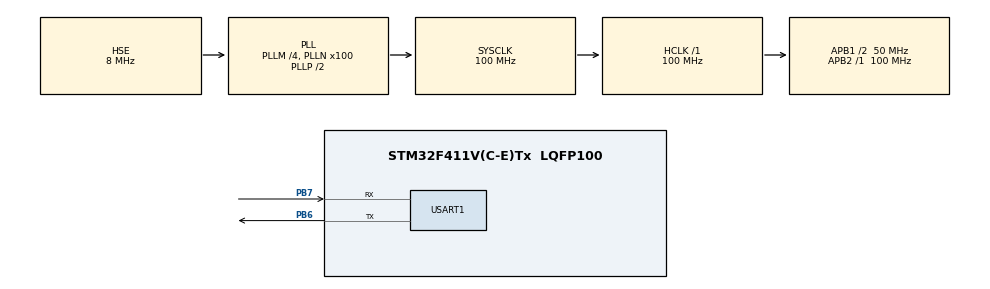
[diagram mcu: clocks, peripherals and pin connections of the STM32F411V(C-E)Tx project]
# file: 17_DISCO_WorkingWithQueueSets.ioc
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FREERTOS.Tasks01=defaultTask,24,128,StartDefaultTask,Default,NULL,Dynamic,NULL,NULL
FREERTOS.configUSE_NEWLIB_REENTRANT=0
FREERTOS.configUSE_PREEMPTION=1
Mcu.Family=STM32F4
Mcu.Name=STM32F411V(C-E)Tx
Mcu.Package=LQFP100
NVIC.PriorityGroup=NVIC_PRIORITYGROUP_4
NVIC.TIM1_UP_TIM10_IRQn=true\:15\:0\:false\:false\:true\:false\:false\:true\:true
NVIC.TimeBase=TIM1_UP_TIM10_IRQn
NVIC.TimeBaseIP=TIM1
PA13.GPIO_Label=SWDIO
PA13.Mode=Serial_Wire
PA13.Signal=SYS_JTMS-SWDIO
PA14.GPIO_Label=SWCLK
PA14.Mode=Serial_Wire
PA14.Signal=SYS_JTCK-SWCLK
PB3.GPIO_Label=SWO
PB3.Signal=SYS_JTDO-SWO
PB6.Mode=Asynchronous
PB6.Signal=USART1_TX
PB7.Mode=Asynchronous
PB7.Signal=USART1_RX
PH0\ -\ OSC_IN.GPIO_Label=PH0-OSC_IN
PH0\ -\ OSC_IN.Mode=HSE-External-Oscillator
PH0\ -\ OSC_IN.Signal=RCC_OSC_IN
PH1\ -\ OSC_OUT.GPIO_Label=PH1-OSC_OUT
PH1\ -\ OSC_OUT.Mode=HSE-External-Oscillator
PH1\ -\ OSC_OUT.Signal=RCC_OSC_OUT
ProjectManager.HeapSize=0x200
ProjectManager.StackSize=0x400
ProjectManager.TargetToolchain=STM32CubeIDE
RCC.48MHZClocksFreq_Value=25000000
RCC.AHBFreq_Value=100000000
RCC.APB1CLKDivider=RCC_HCLK_DIV2
RCC.APB1Freq_Value=50000000
RCC.APB1TimFreq_Value=100000000
RCC.APB2Freq_Value=100000000
RCC.APB2TimFreq_Value=100000000
RCC.CortexFreq_Value=100000000
RCC.HCLKFreq_Value=100000000
RCC.HSE_VALUE=8000000
RCC.HSI_VALUE=16000000
RCC.LSE_VALUE=32768
RCC.PLLI2SM=5
RCC.PLLI2SN=200
RCC.PLLM=4
RCC.PLLN=100
RCC.PLLQ=8
RCC.PLLSourceVirtual=RCC_PLLSOURCE_HSE
RCC.SYSCLKFreq_VALUE=100000000
RCC.SYSCLKSource=RCC_SYSCLKSOURCE_PLLCLK
RCC.VCOOutputFreq_Value=200000000
USART1.VirtualMode=VM_ASYNC
VP_FREERTOS_VS_CMSIS_V2.Mode=CMSIS_V2
VP_SYS_VS_tim1.Mode=TIM1
board=STM32F411E-DISCO

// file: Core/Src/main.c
/* USER CODE BEGIN Header */
/**
  ******************************************************************************
  * @file           : main.c
  * @brief          : Main program body
  ******************************************************************************
  * @attention
  *
  * Copyright (c) 2023 STMicroelectronics.
  * All rights reserved.
  *
  * This software is licensed under terms that can be found in the LICENSE file
  * in the root directory of this software component.
  * If no LICENSE file comes with this software, it is provided AS-IS.
  *
  ******************************************************************************
  */
/* USER CODE END Header */
#include "main.h"
#include "cmsis_os.h"

/* USER CODE BEGIN Includes */
#include "stdio.h"
#include "queue.h"
/* USER CODE END Includes */

UART_HandleTypeDef huart1;

/* Definitions for defaultTask */
//osThreadId_t defaultTaskHandle;
//const osThreadAttr_t defaultTask_attributes = {
//  .name = "defaultTask",
//  .stack_size = 128 * 4,
//  .priority = (osPriority_t) osPriorityNormal,
//};
/* USER CODE BEGIN PV */
static QueueHandle_t xQueue1 = NULL, xQueue2 = NULL;		// Declare two queues
static QueueSetHandle_t xQueueSet = NULL;					// Declare a queue set
/* USER CODE END PV */

void SystemClock_Config(void);
static void MX_GPIO_Init(void);
static void MX_USART1_UART_Init(void);
//void StartDefaultTask(void *argument);

/* USER CODE BEGIN PFP */
void vSenderTask1(void *pvParameters);
void vSenderTask2(void *pvParameters);
void vReceiverTask (void *pvParameters);
int uart1_write(int ch);
int __io_putchar(int ch);
/* USER CODE END PFP */

int main(void)
{

  /* MCU Configuration--------------------------------------------------------*/

  /* Reset of all peripherals, Initializes the Flash interface and the Systick. */
  HAL_Init();

  /* Configure the system clock */
  SystemClock_Config();

  /* Initialize all configured peripherals */
  MX_GPIO_Init();
  MX_USART1_UART_Init();
  /* USER CODE BEGIN 2 */
  printf("System initializing");
  // Create two queues, each sends a character pointer
  xQueue1 = xQueueCreate(1, sizeof(char *));
  xQueue2 = xQueueCreate(1, sizeof(char *));

  // Create the queue set to hold 2 queues
  // Each queue holds 1 element
  xQueueSet = xQueueCreateSet(1 * 2);

  // Add queues to the queue set
  xQueueAddToSet( xQueue1, xQueueSet);
  xQueueAddToSet( xQueue2, xQueueSet);

  // Create two sender tasks with the same priority of 1
  xTaskCreate(vSenderTask1, "Sender1", 100, NULL, 1, NULL);
  xTaskCreate(vSenderTask2, "Sender2", 100, NULL, 1, NULL);

  // Create the receiver task with the higher priority of 2
  xTaskCreate(vReceiverTask, "Receiver", 100, NULL, 2, NULL);

  vTaskStartScheduler();
  /* USER CODE END 2 */

  /* Init scheduler */
//  osKernelInitialize();

  /* Create the thread(s) */
  /* creation of defaultTask */
//  defaultTaskHandle = osThreadNew(StartDefaultTask, NULL, &defaultTask_attributes);

  /* Start scheduler */
//  osKernelStart();

  /* We should never get here as control is now taken by the scheduler */
  /* Infinite loop */
  while (1)
  {

  }
}

void SystemClock_Config(void)
{
  RCC_OscInitTypeDef RCC_OscInitStruct = {0};
  RCC_ClkInitTypeDef RCC_ClkInitStruct = {0};

  /** Configure the main internal regulator output voltage
  */
  __HAL_RCC_PWR_CLK_ENABLE();
  __HAL_PWR_VOLTAGESCALING_CONFIG(PWR_REGULATOR_VOLTAGE_SCALE1);

  /** Initializes the RCC Oscillators according to the specified parameters
  * in the RCC_OscInitTypeDef structure.
  */
  RCC_OscInitStruct.OscillatorType = RCC_OSCILLATORTYPE_HSE;
  RCC_OscInitStruct.HSEState = RCC_HSE_ON;
  RCC_OscInitStruct.PLL.PLLState = RCC_PLL_ON;
  RCC_OscInitStruct.PLL.PLLSource = RCC_PLLSOURCE_HSE;
  RCC_OscInitStruct.PLL.PLLM = 4;
  RCC_OscInitStruct.PLL.PLLN = 100;
  RCC_OscInitStruct.PLL.PLLP = RCC_PLLP_DIV2;
  RCC_OscInitStruct.PLL.PLLQ = 8;
  if (HAL_RCC_OscConfig(&RCC_OscInitStruct) != HAL_OK)
  {
    Error_Handler();
  }

  /** Initializes the CPU, AHB and APB buses clocks
  */
  RCC_ClkInitStruct.ClockType = RCC_CLOCKTYPE_HCLK|RCC_CLOCKTYPE_SYSCLK
                              |RCC_CLOCKTYPE_PCLK1|RCC_CLOCKTYPE_PCLK2;
  RCC_ClkInitStruct.SYSCLKSource = RCC_SYSCLKSOURCE_PLLCLK;
  RCC_ClkInitStruct.AHBCLKDivider = RCC_SYSCLK_DIV1;
  RCC_ClkInitStruct.APB1CLKDivider = RCC_HCLK_DIV2;
  RCC_ClkInitStruct.APB2CLKDivider = RCC_HCLK_DIV1;

  if (HAL_RCC_ClockConfig(&RCC_ClkInitStruct, FLASH_LATENCY_3) != HAL_OK)
  {
    Error_Handler();
  }
}

static void MX_USART1_UART_Init(void)
{

  huart1.Instance = USART1;
  huart1.Init.BaudRate = 115200;
  huart1.Init.WordLength = UART_WORDLENGTH_8B;
  huart1.Init.StopBits = UART_STOPBITS_1;
  huart1.Init.Parity = UART_PARITY_NONE;
  huart1.Init.Mode = UART_MODE_TX_RX;
  huart1.Init.HwFlowCtl = UART_HWCONTROL_NONE;
  huart1.Init.OverSampling = UART_OVERSAMPLING_16;
  if (HAL_UART_Init(&huart1) != HAL_OK)
  {
    Error_Handler();
  }

}

static void MX_GPIO_Init(void)
{

  /* GPIO Ports Clock Enable */
  __HAL_RCC_GPIOH_CLK_ENABLE();
  __HAL_RCC_GPIOA_CLK_ENABLE();
  __HAL_RCC_GPIOB_CLK_ENABLE();

}

/* USER CODE BEGIN 4 */
void vSenderTask1(void *pvParameters)
{
	const TickType_t xBlockTime = pdMS_TO_TICKS(100);
	const char * const msg = "Message from vSendTask1\r\n";
	while(1)
	{
		vTaskDelay(xBlockTime);			// Block for 100 ms
		xQueueSend(xQueue1, &msg, 0);	// Send the string "msg" to xQueue1
	}
}

void vSenderTask2(void *pvParameters)
{
	const TickType_t xBlockTime = pdMS_TO_TICKS(200);
	const char * const msg = "Message from vSendTask2\r\n";
	while(1)
	{
		vTaskDelay(xBlockTime);			// Block for 200 ms
		xQueueSend(xQueue2, &msg, 0);	// Send the string "msg" to xQueue1
	}
}
void vReceiverTask (void *pvParameters)
{
	QueueHandle_t xQueueThatContainsData;
	char * pcReceivedString;

	while(1)
	{
		xQueueThatContainsData = (QueueHandle_t) xQueueSelectFromSet(xQueueSet, portMAX_DELAY);
		xQueueReceive(xQueueThatContainsData, &pcReceivedString, 0);		// Receive data from the queue whose handle has been just returned
		printf(pcReceivedString);

	}
}

int uart1_write(int ch)
{
	while(!(USART1->SR & 0x0080)) {}
	USART1->DR = (ch & 0xFF);
	return ch;
}

int __io_putchar(int ch)
{
	uart1_write(ch);
	return ch;
}

/* USER CODE END 4 */

//void StartDefaultTask(void *argument)
//{
//  /* USER CODE BEGIN 5 */
//  /* Infinite loop */
//  for(;;)
//  {
//    osDelay(1);
//  }
//  /* USER CODE END 5 */
//}

void HAL_TIM_PeriodElapsedCallback(TIM_HandleTypeDef *htim)
{
  if (htim->Instance == TIM1) {
    HAL_IncTick();
  }
}

void Error_Handler(void)
{
  __disable_irq();
  while (1)
  {
  }
}
